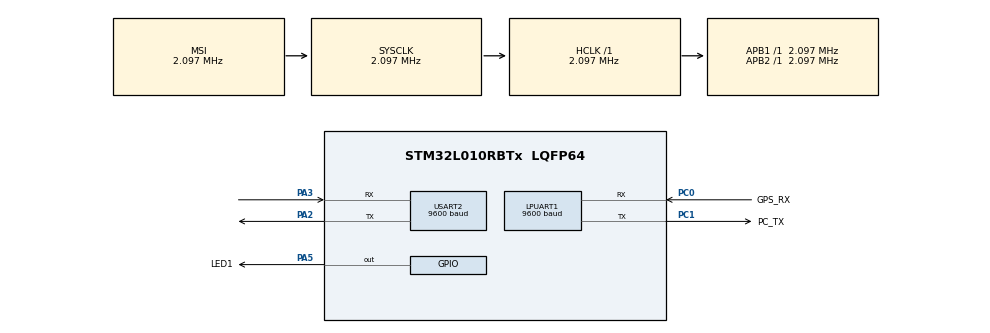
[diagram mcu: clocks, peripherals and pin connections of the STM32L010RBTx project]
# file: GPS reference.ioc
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LPUART1.BaudRate=9600
LPUART1.WordLength=UART_WORDLENGTH_8B
Mcu.Family=STM32L0
Mcu.Name=STM32L010RBTx
Mcu.Package=LQFP64
NVIC.LPUART1_IRQn=true\:0\:0\:false\:false\:true\:true\:true\:true
PA13.Mode=Serial_Wire
PA13.Signal=SYS_SWDIO
PA14.Mode=Serial_Wire
PA14.Signal=SYS_SWCLK
PA2.GPIO_PuPd=GPIO_PULLUP
PA2.Mode=Asynchronous
PA2.Signal=USART2_TX
PA3.GPIO_PuPd=GPIO_PULLUP
PA3.Mode=Asynchronous
PA3.Signal=USART2_RX
PA5.GPIO_Label=LED1
PA5.Signal=GPIO_Output
PC0.GPIO_Label=GPS_RX
PC0.Mode=Asynchronous
PC0.Signal=LPUART1_RX
PC1.GPIO_Label=PC_TX
PC1.Mode=Asynchronous
PC1.Signal=LPUART1_TX
ProjectManager.HeapSize=0x200
ProjectManager.StackSize=0x400
ProjectManager.TargetToolchain=STM32CubeIDE
RCC.AHBFreq_Value=2097000
RCC.APB1Freq_Value=2097000
RCC.APB1TimFreq_Value=2097000
RCC.APB2Freq_Value=2097000
RCC.APB2TimFreq_Value=2097000
RCC.HSE_VALUE=8000000
RCC.HSI16_VALUE=16000000
RCC.HSI_VALUE=16000000
RCC.LSE_VALUE=32768
RCC.MSI_VALUE=2097000
RCC.SYSCLKFreq_VALUE=2097000
RCC.VCOOutputFreq_Value=48000000
USART2.BaudRate=9600
USART2.VirtualMode-Asynchronous=VM_ASYNC
board=custom

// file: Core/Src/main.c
/* USER CODE BEGIN Header */
/**
  ******************************************************************************
  * @file           : main.c
  * @brief          : Main program body
  ******************************************************************************
  * @attention
  *
  * Copyright (c) 2023 STMicroelectronics.
  * All rights reserved.
  *
  * This software is licensed under terms that can be found in the LICENSE file
  * in the root directory of this software component.
  * If no LICENSE file comes with this software, it is provided AS-IS.
  *
  ******************************************************************************
  */
/* USER CODE END Header */
#include "main.h"
#include "usart.h"
#include "gpio.h"

/* USER CODE BEGIN Includes */
#include <stdlib.h>
#include <stdio.h>
/* USER CODE END Includes */

void SystemClock_Config(void);

int main(void)
{
  /* USER CODE BEGIN 1 */
  char UART1_rxBuffer[500];
  /* USER CODE END 1 */

  /* MCU Configuration--------------------------------------------------------*/

  /* Reset of all peripherals, Initializes the Flash interface and the Systick. */
  HAL_Init();

  /* Configure the system clock */
  SystemClock_Config();

  /* Initialize all configured peripherals */
  MX_GPIO_Init();
  MX_LPUART1_UART_Init();
  MX_USART2_UART_Init();
  /* USER CODE BEGIN 2 */
  HAL_UART_MspInit(&hlpuart1);
  HAL_UART_MspInit(&huart2);
  /* USER CODE END 2 */

  /* Infinite loop */
  /* USER CODE BEGIN WHILE */
  while (1)
  {
	  HAL_GPIO_TogglePin (LED1_GPIO_Port, LED1_Pin);

	  HAL_UART_Receive (&hlpuart1, UART1_rxBuffer, sizeof(UART1_rxBuffer), 5000);
	  printf("%s", UART1_rxBuffer);
	  HAL_UART_Transmit (&hlpuart1, UART1_rxBuffer, sizeof(UART1_rxBuffer), 5000);
	  HAL_UART_Transmit (&huart2, "b \n", 1, 5000);

	  HAL_GPIO_TogglePin (LED1_GPIO_Port, LED1_Pin);
	  HAL_Delay (1000);

    /* USER CODE END WHILE */

  }
}

void SystemClock_Config(void)
{
  RCC_OscInitTypeDef RCC_OscInitStruct = {0};
  RCC_ClkInitTypeDef RCC_ClkInitStruct = {0};
  RCC_PeriphCLKInitTypeDef PeriphClkInit = {0};

  /** Configure the main internal regulator output voltage
  */
  __HAL_PWR_VOLTAGESCALING_CONFIG(PWR_REGULATOR_VOLTAGE_SCALE1);

  /** Initializes the RCC Oscillators according to the specified parameters
  * in the RCC_OscInitTypeDef structure.
  */
  RCC_OscInitStruct.OscillatorType = RCC_OSCILLATORTYPE_MSI;
  RCC_OscInitStruct.MSIState = RCC_MSI_ON;
  RCC_OscInitStruct.MSICalibrationValue = 0;
  RCC_OscInitStruct.MSIClockRange = RCC_MSIRANGE_5;
  RCC_OscInitStruct.PLL.PLLState = RCC_PLL_NONE;
  if (HAL_RCC_OscConfig(&RCC_OscInitStruct) != HAL_OK)
  {
    Error_Handler();
  }

  /** Initializes the CPU, AHB and APB buses clocks
  */
  RCC_ClkInitStruct.ClockType = RCC_CLOCKTYPE_HCLK|RCC_CLOCKTYPE_SYSCLK
                              |RCC_CLOCKTYPE_PCLK1|RCC_CLOCKTYPE_PCLK2;
  RCC_ClkInitStruct.SYSCLKSource = RCC_SYSCLKSOURCE_MSI;
  RCC_ClkInitStruct.AHBCLKDivider = RCC_SYSCLK_DIV1;
  RCC_ClkInitStruct.APB1CLKDivider = RCC_HCLK_DIV1;
  RCC_ClkInitStruct.APB2CLKDivider = RCC_HCLK_DIV1;

  if (HAL_RCC_ClockConfig(&RCC_ClkInitStruct, FLASH_LATENCY_0) != HAL_OK)
  {
    Error_Handler();
  }
  PeriphClkInit.PeriphClockSelection = RCC_PERIPHCLK_USART2|RCC_PERIPHCLK_LPUART1;
  PeriphClkInit.Usart2ClockSelection = RCC_USART2CLKSOURCE_PCLK1;
  PeriphClkInit.Lpuart1ClockSelection = RCC_LPUART1CLKSOURCE_PCLK1;
  if (HAL_RCCEx_PeriphCLKConfig(&PeriphClkInit) != HAL_OK)
  {
    Error_Handler();
  }
}

void Error_Handler(void)
{
  __disable_irq();
  while (1)
  {
  }
}
